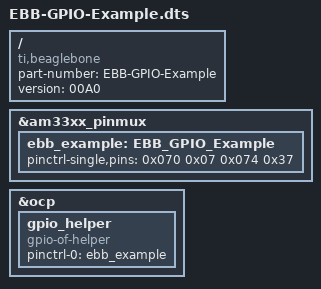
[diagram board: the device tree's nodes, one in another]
/*  
* Copyright (C) 2012 Texas Instruments Incorporated - http://www.ti.com/
*
* This program is free software; you can redistribute it and/or modify
* it under the terms of the GNU General Purpose License Version 2 as
* published by the Free Software Foundation
*
* Original from: github.com/jadonk/validation-scripts/blob/master/test-capemgr/ 
*
* Modified by Derek Molloy for the example on www.derekmolloy.ie
* that maps GPIO pins for the example
*/

/dts-v1/;
/plugin/;

/{
       compatible = "ti,beaglebone", "ti,beaglebone-black";
       part-number = "EBB-GPIO-Example";
       version = "00A0";

       fragment@0 {
             target = <&am33xx_pinmux>;
            
             __overlay__ {
                  ebb_example: EBB_GPIO_Example {
			pinctrl-single,pins = <
                                0x070 0x07  // P9_11 PINS$28 GPIO0_30 = 30 Output Mode7 pulldown
                                0x074 0x37  // P9_13 PINS$29 GPIO0_31 = 31 Input Mode7 pullup 
  
                               /* OUTPUT  GPIO(mode7) 0x07 pulldown, 0x17 pullup, 0x?f no pullup/down */
			       /* INPUT   GPIO(mode7) 0x27 pulldown, 0x37 pullup, 0x?f no pullup/down */
			>;
		  };
             };
       };

       fragment@1 {
		target = <&ocp>;
		__overlay__ {
			gpio_helper {
				compatible = "gpio-of-helper";
				status = "okay";
				pinctrl-names = "default";
				pinctrl-0 = <&ebb_example>;
			};
		};
	};
};
